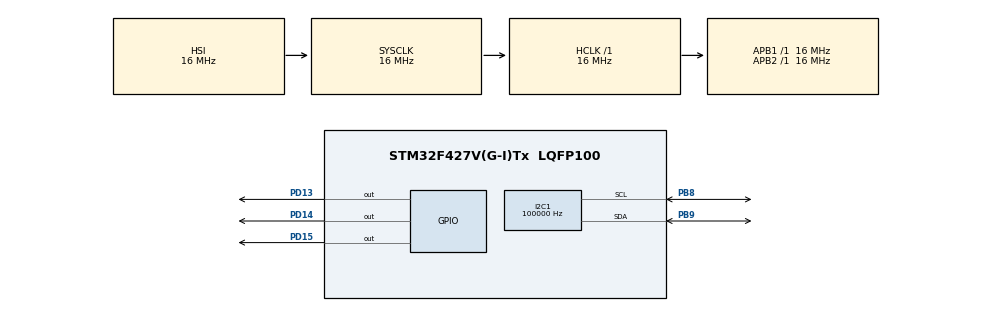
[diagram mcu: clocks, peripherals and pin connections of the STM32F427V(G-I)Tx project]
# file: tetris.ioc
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FREERTOS.Tasks01=defaultTask,1,384,StartDefaultTask,Default,NULL,Dynamic,NULL,NULL;myTask02,0,512,StartTask02,Default,NULL,Dynamic,NULL,NULL;displayTask,-1,512,StartDisplayTask,Default,NULL,Dynamic,NULL,NULL
Mcu.Family=STM32F4
Mcu.Name=STM32F427V(G-I)Tx
Mcu.Package=LQFP100
NVIC.PriorityGroup=NVIC_PRIORITYGROUP_4
NVIC.TIM1_UP_TIM10_IRQn=true\:15\:0\:false\:false\:true\:false\:false\:true\:true
NVIC.TimeBase=TIM1_UP_TIM10_IRQn
NVIC.TimeBaseIP=TIM1
PA13.Mode=JTAG_5_pins
PA13.Signal=SYS_JTMS-SWDIO
PA14.Mode=JTAG_5_pins
PA14.Signal=SYS_JTCK-SWCLK
PA15.Mode=JTAG_5_pins
PA15.Signal=SYS_JTDI
PB3.Mode=JTAG_5_pins
PB3.Signal=SYS_JTDO-SWO
PB4.Mode=JTAG_5_pins
PB4.Signal=SYS_JTRST
PD13.Signal=GPIO_Output
PD14.Signal=GPIO_Output
PD15.Signal=GPIO_Output
ProjectManager.HeapSize=0x200
ProjectManager.StackSize=0x400
ProjectManager.TargetToolchain=STM32CubeIDE
RCC.AHBFreq_Value=16000000
RCC.APB1Freq_Value=16000000
RCC.APB2Freq_Value=16000000
RCC.CortexFreq_Value=16000000
RCC.HSE_VALUE=25000000
RCC.HSI_VALUE=16000000
RCC.LSE_VALUE=32768
RCC.SYSCLKFreq_VALUE=16000000
RCC.VCOOutputFreq_Value=192000000
VP_FREERTOS_VS_CMSIS_V1.Mode=CMSIS_V1
VP_SYS_VS_tim1.Mode=TIM1
board=custom
FREERTOS.INCLUDE_vTaskDelayUntil=1
I2C1.ClockSpeed=100000
PB8.Mode=I2C
PB8.Signal=I2C1_SCL
PB8.GPIO_PuPd=GPIO_PULLUP
PB9.Mode=I2C
PB9.Signal=I2C1_SDA
PB9.GPIO_PuPd=GPIO_PULLUP

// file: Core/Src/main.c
/* USER CODE BEGIN Header */
/**
  ******************************************************************************
  * @file           : main.c
  * @brief          : Main program body
  ******************************************************************************
  * @attention
  *
  * Copyright (c) 2026 STMicroelectronics.
  * All rights reserved.
  *
  * This software is licensed under terms that can be found in the LICENSE file
  * in the root directory of this software component.
  * If no LICENSE file comes with this software, it is provided AS-IS.
  *
  ******************************************************************************
  */
/* USER CODE END Header */
#include "main.h"
#include "cmsis_os.h"

/* USER CODE BEGIN Includes */
#include "app_game.h"
#include "board_game.h"
/* USER CODE END Includes */

I2C_HandleTypeDef hi2c1;
osThreadId displayTaskHandle;
osThreadId defaultTaskHandle;
osThreadId myTask02Handle;

void SystemClock_Config(void);
static void MX_GPIO_Init(void);
static void MX_I2C1_Init(void);
void StartDisplayTask(void const *argument);
void StartDefaultTask(void const * argument);
void StartTask02(void const * argument);

int main(void)
{

  /* MCU Configuration--------------------------------------------------------*/

  /* Reset of all peripherals, Initializes the Flash interface and the Systick. */
  HAL_Init();

  /* Configure the system clock */
  SystemClock_Config();

  /* Initialize all configured peripherals */
  MX_GPIO_Init();
  MX_I2C1_Init();
  /* USER CODE BEGIN 2 */
  Board_Init();
/* USER CODE END 2 */

  /* USER CODE BEGIN RTOS_MUTEX */
  App_Init();
/* USER CODE END RTOS_MUTEX */

  /* Create the thread(s) */
  /* definition and creation of defaultTask */
  osThreadDef(defaultTask, StartDefaultTask, osPriorityAboveNormal, 0, 384);
  defaultTaskHandle = osThreadCreate(osThread(defaultTask), NULL);

  /* definition and creation of myTask02 */
  osThreadDef(myTask02, StartTask02, osPriorityNormal, 0, 512);
  myTask02Handle = osThreadCreate(osThread(myTask02), NULL);

  osThreadDef(displayTask, StartDisplayTask, osPriorityBelowNormal, 0, 512);
  displayTaskHandle = osThreadCreate(osThread(displayTask), NULL);

  /* USER CODE BEGIN RTOS_THREADS */
  if (!defaultTaskHandle || !myTask02Handle || !displayTaskHandle) Error_Handler();
/* USER CODE END RTOS_THREADS */

  /* Start scheduler */
  osKernelStart();

  /* We should never get here as control is now taken by the scheduler */

  /* Infinite loop */
  while (1)
  {

  }
}

void SystemClock_Config(void)
{
  RCC_OscInitTypeDef RCC_OscInitStruct = {0};
  RCC_ClkInitTypeDef RCC_ClkInitStruct = {0};

  /** Configure the main internal regulator output voltage
  */
  __HAL_RCC_PWR_CLK_ENABLE();
  __HAL_PWR_VOLTAGESCALING_CONFIG(PWR_REGULATOR_VOLTAGE_SCALE3);

  /** Initializes the RCC Oscillators according to the specified parameters
  * in the RCC_OscInitTypeDef structure.
  */
  RCC_OscInitStruct.OscillatorType = RCC_OSCILLATORTYPE_HSI;
  RCC_OscInitStruct.HSIState = RCC_HSI_ON;
  RCC_OscInitStruct.HSICalibrationValue = RCC_HSICALIBRATION_DEFAULT;
  RCC_OscInitStruct.PLL.PLLState = RCC_PLL_NONE;
  if (HAL_RCC_OscConfig(&RCC_OscInitStruct) != HAL_OK)
  {
    Error_Handler();
  }

  /** Initializes the CPU, AHB and APB buses clocks
  */
  RCC_ClkInitStruct.ClockType = RCC_CLOCKTYPE_HCLK|RCC_CLOCKTYPE_SYSCLK
                              |RCC_CLOCKTYPE_PCLK1|RCC_CLOCKTYPE_PCLK2;
  RCC_ClkInitStruct.SYSCLKSource = RCC_SYSCLKSOURCE_HSI;
  RCC_ClkInitStruct.AHBCLKDivider = RCC_SYSCLK_DIV1;
  RCC_ClkInitStruct.APB1CLKDivider = RCC_HCLK_DIV1;
  RCC_ClkInitStruct.APB2CLKDivider = RCC_HCLK_DIV1;

  if (HAL_RCC_ClockConfig(&RCC_ClkInitStruct, FLASH_LATENCY_0) != HAL_OK)
  {
    Error_Handler();
  }
}

static void MX_I2C1_Init(void)
{
  hi2c1.Instance = I2C1;
  hi2c1.Init.ClockSpeed = 100000;
  hi2c1.Init.DutyCycle = I2C_DUTYCYCLE_2;
  hi2c1.Init.OwnAddress1 = 0;
  hi2c1.Init.AddressingMode = I2C_ADDRESSINGMODE_7BIT;
  hi2c1.Init.DualAddressMode = I2C_DUALADDRESS_DISABLE;
  hi2c1.Init.OwnAddress2 = 0;
  hi2c1.Init.GeneralCallMode = I2C_GENERALCALL_DISABLE;
  hi2c1.Init.NoStretchMode = I2C_NOSTRETCH_DISABLE;
  if (HAL_I2C_Init(&hi2c1) != HAL_OK) Error_Handler();
}

static void MX_GPIO_Init(void)
{
  GPIO_InitTypeDef GPIO_InitStruct = {0};

  /* GPIO Ports Clock Enable */
  __HAL_RCC_GPIOD_CLK_ENABLE();
  __HAL_RCC_GPIOA_CLK_ENABLE();
  __HAL_RCC_GPIOB_CLK_ENABLE();

  /*Configure GPIO pin Output Level */
  HAL_GPIO_WritePin(GPIOD, GPIO_PIN_13|GPIO_PIN_14|GPIO_PIN_15, GPIO_PIN_RESET);

  /*Configure GPIO pins : PD13 PD14 PD15 */
  GPIO_InitStruct.Pin = GPIO_PIN_13|GPIO_PIN_14|GPIO_PIN_15;
  GPIO_InitStruct.Mode = GPIO_MODE_OUTPUT_PP;
  GPIO_InitStruct.Pull = GPIO_NOPULL;
  GPIO_InitStruct.Speed = GPIO_SPEED_FREQ_LOW;
  HAL_GPIO_Init(GPIOD, &GPIO_InitStruct);

}

void StartDefaultTask(void const * argument)
{
  /* USER CODE BEGIN 5 */
  App_InputTask(argument);
/* USER CODE END 5 */
}

void StartTask02(void const * argument)
{
  /* USER CODE BEGIN StartTask02 */
  App_GameTask(argument);
/* USER CODE END StartTask02 */
}

/* USER CODE BEGIN Header_StartDisplayTask */
/* OLED owner task. */
/* USER CODE END Header_StartDisplayTask */
void StartDisplayTask(void const *argument)
{
  /* USER CODE BEGIN StartDisplayTask */
  App_DisplayTask(argument);
  /* USER CODE END StartDisplayTask */
}

void HAL_TIM_PeriodElapsedCallback(TIM_HandleTypeDef *htim)
{
  if (htim->Instance == TIM1)
  {
    HAL_IncTick();
  }
}

void Error_Handler(void)
{
  /* USER CODE BEGIN Error_Handler_Debug */
  __HAL_RCC_GPIOD_CLK_ENABLE();
  GPIOD->BSRR = GPIO_PIN_14 | ((uint32_t)(GPIO_PIN_13 | GPIO_PIN_15) << 16);
  __disable_irq();
  while (1) { }
/* USER CODE END Error_Handler_Debug */
}
